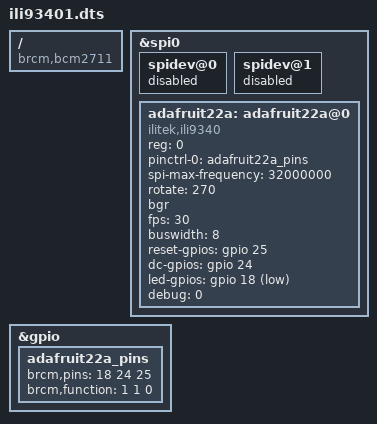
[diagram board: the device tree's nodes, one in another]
/dts-v1/;
/plugin/;


/ {
	compatible = "brcm,bcm2711";

	fragment@0 {
		target = <&spi0>;
		__overlay__ {
			status = "okay";

			spidev@0{
				status="disabled";
			};

			spidev@1{

				status="disabled";
			};
		};
	};

	fragment@1{
		target = <&gpio>;
		__overlay__ {
			adafruit22a_pins: adafruit22a_pins {
				brcm,pins = <18 24 25>;
				brcm,function = <1 1 0>;
			};
		};
	};

	fragment@2 {
		target = <&spi0>;
		__overlay__ {
			#adreess-cells = <1>;
			#size-cells =<0>;

			adafruit22a: adafruit22a@0{
				compatible = "ilitek,ili9340";
				reg = <0>;
				pinctrl-names = "default";
				pinctrl-0 = <&adafruit22a_pins>;
				
				spi-max-frequency = <32000000>;
				rotate = <270>;
				bgr;
				fps = <30>;
				buswidth = <8>;
				reset-gpios = <&gpio 25 0 >;
				dc-gpios = <&gpio 24 0>;
				led-gpios = <&gpio 18 1>;
				debug = <0>;
			};
		};
	};
	__overrides__ {
		speed =   <&adafruit22a>,"spi-max-frequency:0";
		rotate =  <&adafruit22a>,"rotate:0";
		fps =     <&adafruit22a>,"fps:0";
		debug =   <&adafruit22a>,"debug:0";
	};
};
